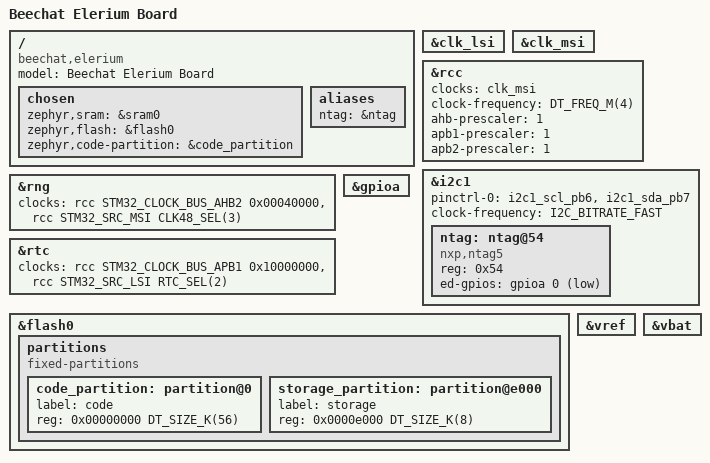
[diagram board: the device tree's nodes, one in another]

/dts-v1/;

#include <st/l4/stm32l412X8.dtsi>
#include <st/l4/stm32l412rbtx-pinctrl.dtsi>

/ {
    model = "Beechat Elerium Board";
    compatible = "beechat,elerium";

    chosen {
        zephyr,sram = &sram0;
        zephyr,flash = &flash0;
        zephyr,code-partition = &code_partition;
    };

    aliases {
        ntag = &ntag;
    };
};

&clk_lsi {
    status = "okay";
};

&clk_msi {
    status = "okay";
};

&rng {
    /delete-property/ clocks;
    clocks = <&rcc STM32_CLOCK_BUS_AHB2 0x00040000>, <&rcc STM32_SRC_MSI CLK48_SEL(3)>;
    status = "okay";
};

&rcc {
    clocks = <&clk_msi>;
    clock-frequency = <DT_FREQ_M(4)>;
    ahb-prescaler = <1>;
    apb1-prescaler = <1>;
    apb2-prescaler = <1>;
};

&i2c1 {
    pinctrl-0 = <&i2c1_scl_pb6 &i2c1_sda_pb7>;
    pinctrl-names = "default";
    clock-frequency = <I2C_BITRATE_FAST>;
    status = "okay";

    ntag: ntag@54 {
        reg = <0x54>;
        compatible = "nxp,ntag5";
        ed-gpios = <&gpioa 0 GPIO_ACTIVE_LOW>;
        status = "okay";
    };
};

&gpioa { 
    status = "okay";
};

&rtc {
    clocks = <&rcc STM32_CLOCK_BUS_APB1 0x10000000>, <&rcc STM32_SRC_LSI RTC_SEL(2)>;
    status = "okay";
};

&flash0 {
    status = "okay";

    partitions {
        compatible = "fixed-partitions";
        #address-cells = <1>;
        #size-cells = <1>;

        code_partition: partition@0 {
            label = "code";
            reg = <0x00000000 DT_SIZE_K(56)>;
        };

        storage_partition: partition@e000 {
            label = "storage";
            reg = <0x0000e000 DT_SIZE_K(8)>;
        };
    };
};

&vref {
    status = "okay";
};

&vbat {
    status = "okay";
};
